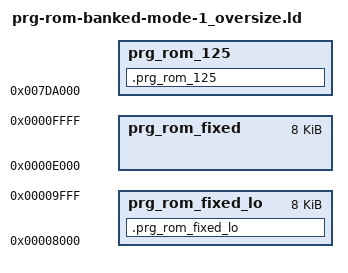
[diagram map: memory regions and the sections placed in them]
PROVIDE(__prg_rom_0 = 0xc000);
PROVIDE(__prg_rom_1 = 0xa000);
PROVIDE(__prg_rom_2 = 0xc000);
PROVIDE(__prg_rom_3 = 0xa000);
PROVIDE(__prg_rom_4 = 0xc000);
PROVIDE(__prg_rom_5 = 0xa000);
PROVIDE(__prg_rom_6 = 0xc000);
PROVIDE(__prg_rom_7 = 0xa000);
PROVIDE(__prg_rom_8 = 0xc000);
PROVIDE(__prg_rom_9 = 0xa000);
PROVIDE(__prg_rom_10 = 0xc000);
PROVIDE(__prg_rom_11 = 0xa000);
PROVIDE(__prg_rom_12 = 0xc000);
PROVIDE(__prg_rom_13 = 0xa000);
PROVIDE(__prg_rom_14 = 0xc000);
PROVIDE(__prg_rom_15 = 0xa000);
PROVIDE(__prg_rom_16 = 0xc000);
PROVIDE(__prg_rom_17 = 0xa000);
PROVIDE(__prg_rom_18 = 0xc000);
PROVIDE(__prg_rom_19 = 0xa000);
PROVIDE(__prg_rom_20 = 0xc000);
PROVIDE(__prg_rom_21 = 0xa000);
PROVIDE(__prg_rom_22 = 0xc000);
PROVIDE(__prg_rom_23 = 0xa000);
PROVIDE(__prg_rom_24 = 0xc000);
PROVIDE(__prg_rom_25 = 0xa000);
PROVIDE(__prg_rom_26 = 0xc000);
PROVIDE(__prg_rom_27 = 0xa000);
PROVIDE(__prg_rom_28 = 0xc000);
PROVIDE(__prg_rom_29 = 0xa000);
PROVIDE(__prg_rom_30 = 0xc000);
PROVIDE(__prg_rom_31 = 0xa000);
PROVIDE(__prg_rom_32 = 0xc000);
PROVIDE(__prg_rom_33 = 0xa000);
PROVIDE(__prg_rom_34 = 0xc000);
PROVIDE(__prg_rom_35 = 0xa000);
PROVIDE(__prg_rom_36 = 0xc000);
PROVIDE(__prg_rom_37 = 0xa000);
PROVIDE(__prg_rom_38 = 0xc000);
PROVIDE(__prg_rom_39 = 0xa000);
PROVIDE(__prg_rom_40 = 0xc000);
PROVIDE(__prg_rom_41 = 0xa000);
PROVIDE(__prg_rom_42 = 0xc000);
PROVIDE(__prg_rom_43 = 0xa000);
PROVIDE(__prg_rom_44 = 0xc000);
PROVIDE(__prg_rom_45 = 0xa000);
PROVIDE(__prg_rom_46 = 0xc000);
PROVIDE(__prg_rom_47 = 0xa000);
PROVIDE(__prg_rom_48 = 0xc000);
PROVIDE(__prg_rom_49 = 0xa000);
PROVIDE(__prg_rom_50 = 0xc000);
PROVIDE(__prg_rom_51 = 0xa000);
PROVIDE(__prg_rom_52 = 0xc000);
PROVIDE(__prg_rom_53 = 0xa000);
PROVIDE(__prg_rom_54 = 0xc000);
PROVIDE(__prg_rom_55 = 0xa000);
PROVIDE(__prg_rom_56 = 0xc000);
PROVIDE(__prg_rom_57 = 0xa000);
PROVIDE(__prg_rom_58 = 0xc000);
PROVIDE(__prg_rom_59 = 0xa000);
PROVIDE(__prg_rom_60 = 0xc000);
PROVIDE(__prg_rom_61 = 0xa000);
PROVIDE(__prg_rom_62 = 0xc000);
PROVIDE(__prg_rom_63 = 0xa000);
PROVIDE(__prg_rom_64 = 0xc000);
PROVIDE(__prg_rom_65 = 0xa000);
PROVIDE(__prg_rom_66 = 0xc000);
PROVIDE(__prg_rom_67 = 0xa000);
PROVIDE(__prg_rom_68 = 0xc000);
PROVIDE(__prg_rom_69 = 0xa000);
PROVIDE(__prg_rom_70 = 0xc000);
PROVIDE(__prg_rom_71 = 0xa000);
PROVIDE(__prg_rom_72 = 0xc000);
PROVIDE(__prg_rom_73 = 0xa000);
PROVIDE(__prg_rom_74 = 0xc000);
PROVIDE(__prg_rom_75 = 0xa000);
PROVIDE(__prg_rom_76 = 0xc000);
PROVIDE(__prg_rom_77 = 0xa000);
PROVIDE(__prg_rom_78 = 0xc000);
PROVIDE(__prg_rom_79 = 0xa000);
PROVIDE(__prg_rom_80 = 0xc000);
PROVIDE(__prg_rom_81 = 0xa000);
PROVIDE(__prg_rom_82 = 0xc000);
PROVIDE(__prg_rom_83 = 0xa000);
PROVIDE(__prg_rom_84 = 0xc000);
PROVIDE(__prg_rom_85 = 0xa000);
PROVIDE(__prg_rom_86 = 0xc000);
PROVIDE(__prg_rom_87 = 0xa000);
PROVIDE(__prg_rom_88 = 0xc000);
PROVIDE(__prg_rom_89 = 0xa000);
PROVIDE(__prg_rom_90 = 0xc000);
PROVIDE(__prg_rom_91 = 0xa000);
PROVIDE(__prg_rom_92 = 0xc000);
PROVIDE(__prg_rom_93 = 0xa000);
PROVIDE(__prg_rom_94 = 0xc000);
PROVIDE(__prg_rom_95 = 0xa000);
PROVIDE(__prg_rom_96 = 0xc000);
PROVIDE(__prg_rom_97 = 0xa000);
PROVIDE(__prg_rom_98 = 0xc000);
PROVIDE(__prg_rom_99 = 0xa000);
PROVIDE(__prg_rom_100 = 0xc000);
PROVIDE(__prg_rom_101 = 0xa000);
PROVIDE(__prg_rom_102 = 0xc000);
PROVIDE(__prg_rom_103 = 0xa000);
PROVIDE(__prg_rom_104 = 0xc000);
PROVIDE(__prg_rom_105 = 0xa000);
PROVIDE(__prg_rom_106 = 0xc000);
PROVIDE(__prg_rom_107 = 0xa000);
PROVIDE(__prg_rom_108 = 0xc000);
PROVIDE(__prg_rom_109 = 0xa000);
PROVIDE(__prg_rom_110 = 0xc000);
PROVIDE(__prg_rom_111 = 0xa000);
PROVIDE(__prg_rom_112 = 0xc000);
PROVIDE(__prg_rom_113 = 0xa000);
PROVIDE(__prg_rom_114 = 0xc000);
PROVIDE(__prg_rom_115 = 0xa000);
PROVIDE(__prg_rom_116 = 0xc000);
PROVIDE(__prg_rom_117 = 0xa000);
PROVIDE(__prg_rom_118 = 0xc000);
PROVIDE(__prg_rom_119 = 0xa000);
PROVIDE(__prg_rom_120 = 0xc000);
PROVIDE(__prg_rom_121 = 0xa000);
PROVIDE(__prg_rom_122 = 0xc000);
PROVIDE(__prg_rom_123 = 0xa000);
PROVIDE(__prg_rom_124 = 0xc000);
PROVIDE(__prg_rom_125 = 0xa000);

__prg_rom_total_fixed_size = 0x4000;

INCLUDE _prg-rom-banked_oversize.ld

INPUT(reset-banked-mode-1.o)

__prg_rom_125_lma       = 0x7da000;
__prg_rom_fixed_lo_lma = 0x008000;
__prg_rom_fixed_lma    = 0x00e000;

__prg_rom_125_offset       = 0xfa000;
__prg_rom_fixed_lo_offset = __prg_rom_size * 1024 - 0x4000;
__prg_rom_fixed_offset    = __prg_rom_size * 1024 - 0x2000;

MEMORY {
  prg_rom_125       : ORIGIN = __prg_rom_125_lma,       LENGTH = __prg_rom_size == 1024 ? 0x2000 : 0
  prg_rom_fixed_lo : ORIGIN = __prg_rom_fixed_lo_lma, LENGTH = 0x2000
  prg_rom_fixed    : ORIGIN = __prg_rom_fixed_lma,    LENGTH = 0x2000
}
REGION_ALIAS("c_readonly", prg_rom_fixed)

SECTIONS {
  .prg_rom_125       : { *(.prg_rom_125       .prg_rom_125.*)       } >prg_rom_125
  .prg_rom_fixed_lo : { *(.prg_rom_fixed_lo .prg_rom_fixed_lo.*) } >prg_rom_fixed_lo
}

INCLUDE _reset.ld

OUTPUT_FORMAT {
  INCLUDE ines-header.ld
  FULL(prg_rom_0)
  FULL(prg_rom_1)
  FULL(prg_rom_2)
  FULL(prg_rom_3)
  FULL(prg_rom_4)
  FULL(prg_rom_5)
  FULL(prg_rom_6)
  FULL(prg_rom_7)
  FULL(prg_rom_8)
  FULL(prg_rom_9)
  FULL(prg_rom_10)
  FULL(prg_rom_11)
  FULL(prg_rom_12)
  FULL(prg_rom_13)
  FULL(prg_rom_14)
  FULL(prg_rom_15)
  FULL(prg_rom_16)
  FULL(prg_rom_17)
  FULL(prg_rom_18)
  FULL(prg_rom_19)
  FULL(prg_rom_20)
  FULL(prg_rom_21)
  FULL(prg_rom_22)
  FULL(prg_rom_23)
  FULL(prg_rom_24)
  FULL(prg_rom_25)
  FULL(prg_rom_26)
  FULL(prg_rom_27)
  FULL(prg_rom_28)
  FULL(prg_rom_29)
  FULL(prg_rom_30)
  FULL(prg_rom_31)
  FULL(prg_rom_32)
  FULL(prg_rom_33)
  FULL(prg_rom_34)
  FULL(prg_rom_35)
  FULL(prg_rom_36)
  FULL(prg_rom_37)
  FULL(prg_rom_38)
  FULL(prg_rom_39)
  FULL(prg_rom_40)
  FULL(prg_rom_41)
  FULL(prg_rom_42)
  FULL(prg_rom_43)
  FULL(prg_rom_44)
  FULL(prg_rom_45)
  FULL(prg_rom_46)
  FULL(prg_rom_47)
  FULL(prg_rom_48)
  FULL(prg_rom_49)
  FULL(prg_rom_50)
  FULL(prg_rom_51)
  FULL(prg_rom_52)
  FULL(prg_rom_53)
  FULL(prg_rom_54)
  FULL(prg_rom_55)
  FULL(prg_rom_56)
  FULL(prg_rom_57)
  FULL(prg_rom_58)
  FULL(prg_rom_59)
  FULL(prg_rom_60)
  FULL(prg_rom_61)
  FULL(prg_rom_62)
  FULL(prg_rom_63)
  FULL(prg_rom_64)
  FULL(prg_rom_65)
  FULL(prg_rom_66)
  FULL(prg_rom_67)
  FULL(prg_rom_68)
  FULL(prg_rom_69)
  FULL(prg_rom_70)
  FULL(prg_rom_71)
  FULL(prg_rom_72)
  FULL(prg_rom_73)
  FULL(prg_rom_74)
  FULL(prg_rom_75)
  FULL(prg_rom_76)
  FULL(prg_rom_77)
  FULL(prg_rom_78)
  FULL(prg_rom_79)
  FULL(prg_rom_80)
  FULL(prg_rom_81)
  FULL(prg_rom_82)
  FULL(prg_rom_83)
  FULL(prg_rom_84)
  FULL(prg_rom_85)
  FULL(prg_rom_86)
  FULL(prg_rom_87)
  FULL(prg_rom_88)
  FULL(prg_rom_89)
  FULL(prg_rom_90)
  FULL(prg_rom_91)
  FULL(prg_rom_92)
  FULL(prg_rom_93)
  FULL(prg_rom_94)
  FULL(prg_rom_95)
  FULL(prg_rom_96)
  FULL(prg_rom_97)
  FULL(prg_rom_98)
  FULL(prg_rom_99)
  FULL(prg_rom_100)
  FULL(prg_rom_101)
  FULL(prg_rom_102)
  FULL(prg_rom_103)
  FULL(prg_rom_104)
  FULL(prg_rom_105)
  FULL(prg_rom_106)
  FULL(prg_rom_107)
  FULL(prg_rom_108)
  FULL(prg_rom_109)
  FULL(prg_rom_110)
  FULL(prg_rom_111)
  FULL(prg_rom_112)
  FULL(prg_rom_113)
  FULL(prg_rom_114)
  FULL(prg_rom_115)
  FULL(prg_rom_116)
  FULL(prg_rom_117)
  FULL(prg_rom_118)
  FULL(prg_rom_119)
  FULL(prg_rom_120)
  FULL(prg_rom_121)
  FULL(prg_rom_122)
  FULL(prg_rom_123)
  FULL(prg_rom_124)
  FULL(prg_rom_125)
  FULL(prg_rom_fixed_lo)
  FULL(prg_rom_fixed)
  FULL(chr_rom)
}
